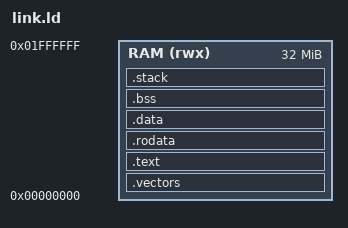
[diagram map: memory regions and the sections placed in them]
MEMORY {
	RAM (rwx): ORIGIN = 0x00000000, LENGTH = 32M
}

ENTRY(_start);

SECTIONS {
	.vectors : {
		KEEP(*(.vectors))
		. = ALIGN(32);
	} >RAM

	.text : {
		*(.text.startup)
		*(.text)
		*(.text.*)
	} >RAM
	
	.rodata : { 
		*(.rodata)
		*(.rodata.*)
	} >RAM
	
	.data : {
		*(.data)
		*(.data.*)
		*(.sdata)
		*(.sdata.*)
	} >RAM
	
	.bss : {
		_sbss = .;
		*(.sbss)
		*(.sbss.*)
		*(.scommon)
		*(.bss)
		*(.bss.*)
		*(COMMON)
		_ebss = .;
	} >RAM
	
	.stack : {
		. = . + 16384;
		. = ALIGN(8);
		__sp_system = .;
	} >RAM
	
	end = .;
}
